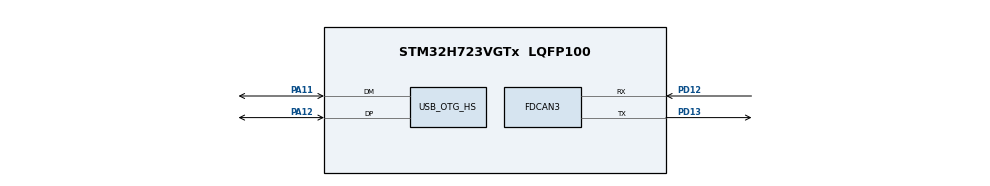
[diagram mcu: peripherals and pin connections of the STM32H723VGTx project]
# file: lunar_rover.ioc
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CORTEX_M7.default_mode_Activation=1
Dma.Request0=UART5_RX
Dma.UART5_RX.0.Direction=DMA_PERIPH_TO_MEMORY
Dma.UART5_RX.0.FIFOMode=DMA_FIFOMODE_DISABLE
Dma.UART5_RX.0.Instance=DMA1_Stream1
Dma.UART5_RX.0.MemDataAlignment=DMA_MDATAALIGN_BYTE
Dma.UART5_RX.0.MemInc=DMA_MINC_ENABLE
Dma.UART5_RX.0.Mode=DMA_NORMAL
Dma.UART5_RX.0.PeriphDataAlignment=DMA_PDATAALIGN_BYTE
Dma.UART5_RX.0.PeriphInc=DMA_PINC_DISABLE
Dma.UART5_RX.0.Priority=DMA_PRIORITY_HIGH
FDCAN3.AutoRetransmission=ENABLE
FDCAN3.CalculateBaudRateNominal=1000000
FDCAN3.CalculateTimeBitNominal=1000
FDCAN3.CalculateTimeQuantumNominal=25.0
FDCAN3.DataPrescaler=3
FDCAN3.DataSyncJumpWidth=5
FDCAN3.DataTimeSeg1=14
FDCAN3.DataTimeSeg2=5
FDCAN3.FrameFormat=FDCAN_FRAME_FD_BRS
FDCAN3.NominalPrescaler=3
FDCAN3.NominalTimeSeg1=29
FDCAN3.NominalTimeSeg2=10
FDCAN3.ProtocolException=ENABLE
FDCAN3.RxFifo0ElmtsNbr=6
FDCAN3.StdFiltersNbr=1
FDCAN3.TransmitPause=ENABLE
FDCAN3.TxFifoQueueElmtsNbr=32
FREERTOS.Tasks01=defaultTask,24,256,StartDefaultTask,As weak,NULL,Dynamic,NULL,NULL;Error,8,128,Error_tasks,As weak,NULL,Dynamic,NULL,NULL;roboARM,8,512,roboARM_task,As weak,NULL,Dynamic,NULL,NULL
Mcu.Family=STM32H7
Mcu.Name=STM32H723VGTx
Mcu.Package=LQFP100
NVIC.DMA1_Stream1_IRQn=true\:5\:0\:false\:false\:true\:true\:false\:true\:true
NVIC.FDCAN3_IT0_IRQn=true\:5\:0\:false\:false\:true\:true\:true\:true\:true
NVIC.FDCAN3_IT1_IRQn=true\:5\:0\:false\:false\:true\:true\:true\:true\:true
NVIC.OTG_HS_IRQn=true\:5\:0\:false\:false\:true\:true\:false\:true\:true
NVIC.PriorityGroup=NVIC_PRIORITYGROUP_4
NVIC.TIM6_DAC_IRQn=true\:15\:0\:false\:false\:true\:false\:false\:true\:true
NVIC.TimeBase=TIM6_DAC_IRQn
NVIC.TimeBaseIP=TIM6
NVIC.UART5_IRQn=true\:5\:0\:false\:false\:true\:true\:true\:true\:true
PA11.Mode=Device_Only_FS
PA11.Signal=USB_OTG_HS_DM
PA12.Mode=Device_Only_FS
PA12.Signal=USB_OTG_HS_DP
PA13(JTMS/SWDIO).Mode=Serial_Wire
PA13(JTMS/SWDIO).Signal=DEBUG_JTMS-SWDIO
PA14(JTCK/SWCLK).Mode=Serial_Wire
PA14(JTCK/SWCLK).Signal=DEBUG_JTCK-SWCLK
PD2.Signal=UART5_RX
PD12.Mode=FDCAN_Activate
PD12.Signal=FDCAN3_RX
PD13.Mode=FDCAN_Activate
PD13.Signal=FDCAN3_TX
PH0-OSC_IN.Mode=HSE-External-Oscillator
PH0-OSC_IN.Signal=RCC_OSC_IN
PH1-OSC_OUT.Mode=HSE-External-Oscillator
PH1-OSC_OUT.Signal=RCC_OSC_OUT
ProjectManager.HeapSize=0x200
ProjectManager.StackSize=0x400
ProjectManager.TargetToolchain=MDK-ARM V5.32
RCC.ADCFreq_Value=80000000
RCC.APB1Freq_Value=120000000
RCC.APB2Freq_Value=120000000
RCC.APB3Freq_Value=120000000
RCC.APB4Freq_Value=120000000
RCC.CortexFreq_Value=480000000
RCC.D1PPRE=RCC_APB3_DIV2
RCC.D2PPRE1=RCC_APB1_DIV2
RCC.D2PPRE2=RCC_APB2_DIV2
RCC.D3PPRE=RCC_APB4_DIV2
RCC.DIVM1=2
RCC.DIVM2=8
RCC.DIVM3=8
RCC.DIVN1=40
RCC.DIVN2=80
RCC.DIVN3=80
RCC.DIVP1=1
RCC.DIVP2=3
RCC.DIVP3=3
RCC.DIVQ1=4
RCC.DIVQ2=3
RCC.DIVQ3=5
RCC.HCLKFreq_Value=240000000
RCC.HPRE=RCC_HCLK_DIV2
RCC.HSE_VALUE=24000000
RCC.PLL2FRACN=0
RCC.PLL3FRACN=0
RCC.PLL3_VCI_Range-AdvancedSettings=RCC_PLL3VCIRANGE_1
RCC.PLL3_VCO_SEL-AdvancedSettings=RCC_PLL3VCOMEDIUM
RCC.PLLFRACN=0
RCC.PLLSourceVirtual=RCC_PLLSOURCE_HSE
RCC.SYSCLKFreq_VALUE=480000000
RCC.SYSCLKSource=RCC_SYSCLKSOURCE_PLLCLK
RCC.USBCLockSelection=RCC_USBCLKSOURCE_PLL3
RCC.USBFreq_Value=48000000
USB_DEVICE.CLASS_NAME_HS=CDC
USB_DEVICE.VirtualMode=Cdc
USB_DEVICE.VirtualModeHS=Cdc_HS
USB_OTG_HS.VirtualMode-Device_Only_FS=Device_Only_FS
UART5.BaudRate=100000
UART5.Parity=PARITY_EVEN
UART5.VirtualMode=VM_ASYNC
UART5.WordLength=WORDLENGTH_9B
VP_FREERTOS_VS_CMSIS_V2.Mode=CMSIS_V2
VP_MEMORYMAP_VS_MEMORYMAP.Mode=CurAppReg
VP_SYS_VS_tim6.Mode=TIM6
VP_USB_DEVICE_VS_USB_DEVICE_CDC_HS.Mode=CDC_HS
board=custom

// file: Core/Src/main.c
/* USER CODE BEGIN Header */
/**
  ******************************************************************************
  * @file           : main.c
  * @brief          : Main program body
  ******************************************************************************
  * @attention
  *
  * Copyright (c) 2026 STMicroelectronics.
  * All rights reserved.
  *
  * This software is licensed under terms that can be found in the LICENSE file
  * in the root directory of this software component.
  * If no LICENSE file comes with this software, it is provided AS-IS.
  *
  ******************************************************************************
  */
/* USER CODE END Header */
#include "main.h"
#include "FreeRTOS.h"
#include "cmsis_os2.h"
#include "dma.h"
#include "fdcan.h"
#include "usart.h"
#include "usb_device.h"
#include "gpio.h"

/* USER CODE BEGIN Includes */
#include "Remote.h"

/* USER CODE END Includes */

void SystemClock_Config(void);
static void MPU_Config(void);
void MX_FREERTOS_Init(void);

int main(void)
{

  /* MPU Configuration--------------------------------------------------------*/
  MPU_Config();

  /* MCU Configuration--------------------------------------------------------*/

  /* Reset of all peripherals, Initializes the Flash interface and the Systick. */
  HAL_Init();

  /* Configure the system clock */
  SystemClock_Config();

  /* Initialize all configured peripherals */
  MX_GPIO_Init();
  MX_DMA_Init();
  MX_FDCAN3_Init();
  MX_UART5_Init();
  /* USER CODE BEGIN 2 */
  Remote_Init();

  /* USER CODE END 2 */

  /* Init scheduler */
  osKernelInitialize();  /* Call init function for freertos objects (in cmsis_os2.c) */
  MX_FREERTOS_Init();

  /* Start scheduler */
  osKernelStart();

  /* We should never get here as control is now taken by the scheduler */

  /* Infinite loop */
  while (1)
  {

  }
}

void SystemClock_Config(void)
{
  RCC_OscInitTypeDef RCC_OscInitStruct = {0};
  RCC_ClkInitTypeDef RCC_ClkInitStruct = {0};

  /** Supply configuration update enable
  */
  HAL_PWREx_ConfigSupply(PWR_LDO_SUPPLY);

  /** Configure the main internal regulator output voltage
  */
  __HAL_PWR_VOLTAGESCALING_CONFIG(PWR_REGULATOR_VOLTAGE_SCALE0);

  while(!__HAL_PWR_GET_FLAG(PWR_FLAG_VOSRDY)) {}

  /** Initializes the RCC Oscillators according to the specified parameters
  * in the RCC_OscInitTypeDef structure.
  */
  RCC_OscInitStruct.OscillatorType = RCC_OSCILLATORTYPE_HSE;
  RCC_OscInitStruct.HSEState = RCC_HSE_ON;
  RCC_OscInitStruct.PLL.PLLState = RCC_PLL_ON;
  RCC_OscInitStruct.PLL.PLLSource = RCC_PLLSOURCE_HSE;
  RCC_OscInitStruct.PLL.PLLM = 2;
  RCC_OscInitStruct.PLL.PLLN = 40;
  RCC_OscInitStruct.PLL.PLLP = 1;
  RCC_OscInitStruct.PLL.PLLQ = 4;
  RCC_OscInitStruct.PLL.PLLR = 2;
  RCC_OscInitStruct.PLL.PLLRGE = RCC_PLL1VCIRANGE_3;
  RCC_OscInitStruct.PLL.PLLVCOSEL = RCC_PLL1VCOWIDE;
  RCC_OscInitStruct.PLL.PLLFRACN = 0;
  if (HAL_RCC_OscConfig(&RCC_OscInitStruct) != HAL_OK)
  {
    Error_Handler();
  }

  /** Initializes the CPU, AHB and APB buses clocks
  */
  RCC_ClkInitStruct.ClockType = RCC_CLOCKTYPE_HCLK|RCC_CLOCKTYPE_SYSCLK
                              |RCC_CLOCKTYPE_PCLK1|RCC_CLOCKTYPE_PCLK2
                              |RCC_CLOCKTYPE_D3PCLK1|RCC_CLOCKTYPE_D1PCLK1;
  RCC_ClkInitStruct.SYSCLKSource = RCC_SYSCLKSOURCE_PLLCLK;
  RCC_ClkInitStruct.SYSCLKDivider = RCC_SYSCLK_DIV1;
  RCC_ClkInitStruct.AHBCLKDivider = RCC_HCLK_DIV2;
  RCC_ClkInitStruct.APB3CLKDivider = RCC_APB3_DIV2;
  RCC_ClkInitStruct.APB1CLKDivider = RCC_APB1_DIV2;
  RCC_ClkInitStruct.APB2CLKDivider = RCC_APB2_DIV2;
  RCC_ClkInitStruct.APB4CLKDivider = RCC_APB4_DIV2;

  if (HAL_RCC_ClockConfig(&RCC_ClkInitStruct, FLASH_LATENCY_3) != HAL_OK)
  {
    Error_Handler();
  }
}

 /* MPU Configuration */

void MPU_Config(void)
{
  MPU_Region_InitTypeDef MPU_InitStruct = {0};

  /* Disables the MPU */
  HAL_MPU_Disable();

  /** Initializes and configures the Region and the memory to be protected
  */
  MPU_InitStruct.Enable = MPU_REGION_ENABLE;
  MPU_InitStruct.Number = MPU_REGION_NUMBER0;
  MPU_InitStruct.BaseAddress = 0x0;
  MPU_InitStruct.Size = MPU_REGION_SIZE_4GB;
  MPU_InitStruct.SubRegionDisable = 0x87;
  MPU_InitStruct.TypeExtField = MPU_TEX_LEVEL0;
  MPU_InitStruct.AccessPermission = MPU_REGION_NO_ACCESS;
  MPU_InitStruct.DisableExec = MPU_INSTRUCTION_ACCESS_DISABLE;
  MPU_InitStruct.IsShareable = MPU_ACCESS_SHAREABLE;
  MPU_InitStruct.IsCacheable = MPU_ACCESS_NOT_CACHEABLE;
  MPU_InitStruct.IsBufferable = MPU_ACCESS_NOT_BUFFERABLE;

  HAL_MPU_ConfigRegion(&MPU_InitStruct);
  /* Enables the MPU */
  HAL_MPU_Enable(MPU_PRIVILEGED_DEFAULT);

}

void HAL_TIM_PeriodElapsedCallback(TIM_HandleTypeDef *htim)
{
  if (htim->Instance == TIM6)
  {
    HAL_IncTick();
  }
}

void Error_Handler(void)
{
  __disable_irq();
  while (1)
  {
  }
}

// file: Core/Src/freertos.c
/* USER CODE BEGIN Header */
/**
  ******************************************************************************
  * File Name          : freertos.c
  * Description        : Code for freertos applications
  ******************************************************************************
  * @attention
  *
  * Copyright (c) 2026 STMicroelectronics.
  * All rights reserved.
  *
  * This software is licensed under terms that can be found in the LICENSE file
  * in the root directory of this software component.
  * If no LICENSE file comes with this software, it is provided AS-IS.
  *
  ******************************************************************************
  */
/* USER CODE END Header */

#include "FreeRTOS.h"
#include "task.h"
#include "main.h"
#include "FreeRTOS.h"
#include "cmsis_os2.h"

/* USER CODE BEGIN Variables */
/* 上位机 USB 链路任务：创建代码手写在下面的 USER CODE 段，重新生成 CubeMX 代码不会丢。 */
osThreadId_t hostTaskHandle;
const osThreadAttr_t hostTask_attributes = {
  .name = "Host",
  .stack_size = 256 * 4,
  .priority = (osPriority_t) osPriorityLow,
};
/* USER CODE END Variables */
/* Definitions for defaultTask */
osThreadId_t defaultTaskHandle;
const osThreadAttr_t defaultTask_attributes = {
  .name = "defaultTask",
  .stack_size = 256 * 4,
  .priority = (osPriority_t) osPriorityNormal,
};
/* Definitions for Error */
osThreadId_t ErrorHandle;
const osThreadAttr_t Error_attributes = {
  .name = "Error",
  .stack_size = 128 * 4,
  .priority = (osPriority_t) osPriorityLow,
};
/* Definitions for roboARM */
osThreadId_t roboARMHandle;
const osThreadAttr_t roboARM_attributes = {
  .name = "roboARM",
  .stack_size = 512 * 4,
  .priority = (osPriority_t) osPriorityLow,
};

/* USER CODE BEGIN FunctionPrototypes */
extern void Host_Task(void *argument);   /* 定义在 others/src/thread/task_host.cpp */
/* USER CODE END FunctionPrototypes */

void StartDefaultTask(void *argument);
void Error_tasks(void *argument);
void roboARM_task(void *argument);

extern void MX_USB_DEVICE_Init(void);
void MX_FREERTOS_Init(void); /* (MISRA C 2004 rule 8.1) */

void MX_FREERTOS_Init(void) {

  /* Create the thread(s) */
  /* creation of defaultTask */
  defaultTaskHandle = osThreadNew(StartDefaultTask, NULL, &defaultTask_attributes);

  /* creation of Error */
  ErrorHandle = osThreadNew(Error_tasks, NULL, &Error_attributes);

  /* creation of roboARM */
  roboARMHandle = osThreadNew(roboARM_task, NULL, &roboARM_attributes);

  /* USER CODE BEGIN RTOS_THREADS */
  /* add threads, ... */
  /* 创建上位机 USB 链路任务（与 roboARM 同级，平时阻塞在信号量上，不抢控制周期） */
  hostTaskHandle = osThreadNew(Host_Task, NULL, &hostTask_attributes);
  /* USER CODE END RTOS_THREADS */

}

__weak void StartDefaultTask(void *argument)
{
  /* init code for USB_DEVICE */
  MX_USB_DEVICE_Init();
  for(;;)
  {
    osDelay(1);
  }
}

__weak void Error_tasks(void *argument)
{
  for(;;)
  {
    osDelay(1);
  }
}

__weak void roboARM_task(void *argument)
{
  for(;;)
  {
    osDelay(1);
  }
}
